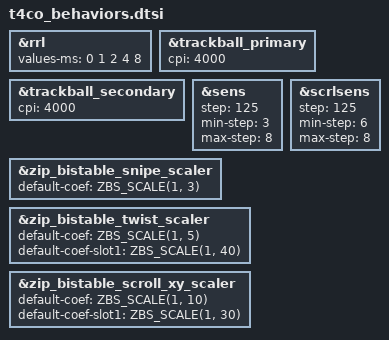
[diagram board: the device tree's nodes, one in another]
/*
 * Polling Rate Setting Overrides
 *
 * 0ms: No delay? report as fast as possible
 * 1ms: 1000Hz
 * 2ms: 500Hz
 * 4ms: 250Hz
 * 8ms: 125Hz
 */
&rrl {
    values-ms = <0 1 2 4 8>;
};


/*
 * Pixart 3395 Overrides
 *
 * Default: 3200
 * Range is 50-25600 in 50 CPI increments
 */
&trackball_primary {
	cpi = <4000>;
};

&trackball_secondary {
	cpi = <4000>;
};



/*
 * Pointer and Twist Scaling
 *
 * How it is used:
 *   CPI * ( step * step increment ) / 1000
 *
 * run pointer at 3
 * run scroll at 7
 * 
 */
&sens {
    step = <125>;
    min-step = <3>;
    max-step = <8>;
};

&scrlsens {
    step = <125>;
    min-step = <6>;
    max-step = <8>;
};



/*
 * Scaling Overrides
 *
 * ZBS_SCALE(multiplier, divisor)
 * coef is windows (default)
 * coef-slot1 is mac
 */
&zip_bistable_snipe_scaler {
	default-coef = <ZBS_SCALE(1, 3)>;
};

&zip_bistable_twist_scaler {
	default-coef = <ZBS_SCALE(1, 5)>;
	default-coef-slot1 = <ZBS_SCALE(1, 40)>;	
};

&zip_bistable_scroll_xy_scaler { 
	default-coef = <ZBS_SCALE(1, 10)>;
	default-coef-slot1 = <ZBS_SCALE(1, 30)>;
};
